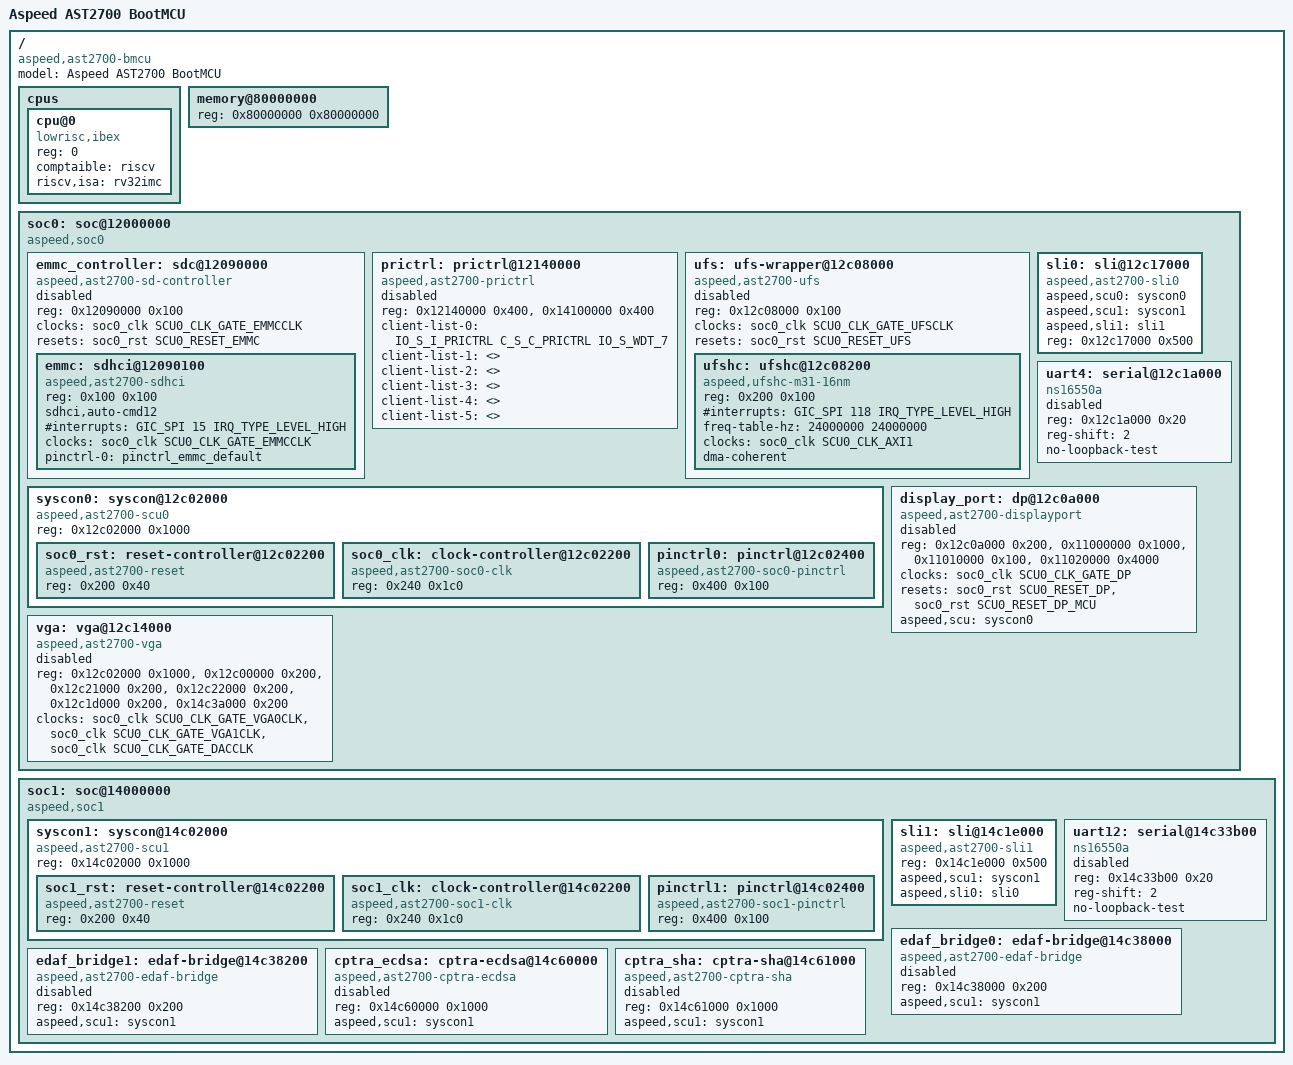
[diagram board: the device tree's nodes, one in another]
// SPDX-License-Identifier: GPL-2.0+
#include <dt-bindings/interrupt-controller/arm-gic.h>
#include <dt-bindings/gpio/aspeed-gpio.h>
#include <dt-bindings/clock/ast2700-clock.h>
#include <dt-bindings/reset/ast2700-reset.h>
#include <dt-bindings/soc/ast2700-prictrl.h>

/ {
	model = "Aspeed AST2700 BootMCU";
	compatible = "aspeed,ast2700-bmcu";
	#address-cells = <1>;
	#size-cells = <1>;

	cpus {
		#address-cells = <1>;
		#size-cells = <0>;

		cpu@0 {
			compatible = "lowrisc,ibex";
			device_type = "cpu";
			reg = <0>;
			comptaible = "riscv";
			riscv,isa = "rv32imc";
		};
	};

	memory@80000000 {
		reg = <0x80000000 0x80000000>;
	};

	soc0: soc@12000000 {
		compatible = "aspeed,soc0","simple-bus";
		#address-cells = <1>;
		#size-cells = <1>;
		ranges;

		emmc_controller: sdc@12090000 {
			compatible = "aspeed,ast2700-sd-controller";
			reg = <0x12090000 0x100>;
			#address-cells = <1>;
			#size-cells = <1>;
			clocks = <&soc0_clk SCU0_CLK_GATE_EMMCCLK>;
			resets = <&soc0_rst SCU0_RESET_EMMC>;
			ranges = <0 0x12090000 0x10000>;
			status = "disabled";

			emmc: sdhci@12090100 {
				compatible = "aspeed,ast2700-sdhci";
				reg = <0x100 0x100>;
				sdhci,auto-cmd12;
				#interrupts = <GIC_SPI 15 IRQ_TYPE_LEVEL_HIGH>;
				clocks = <&soc0_clk SCU0_CLK_GATE_EMMCCLK>;
				pinctrl-names = "default";
				pinctrl-0 = <&pinctrl_emmc_default>;
			};
		};

		prictrl: prictrl@12140000 {
			compatible = "aspeed,ast2700-prictrl";
			reg = <0x12140000 0x400>, <0x14100000 0x400>;
			client-list-0 = <IO_S_I_PRICTRL C_S_C_PRICTRL IO_S_WDT_7>;
			client-list-1 = <>;
			client-list-2 = <>;
			client-list-3 = <>;
			client-list-4 = <>;
			client-list-5 = <>;
			status = "disable";
		};

		ufs: ufs-wrapper@12c08000 {
			compatible = "aspeed,ast2700-ufs";
			reg = <0x12c08000 0x100>;
			#address-cells = <1>;
			#size-cells = <1>;
			ranges = <0 0x12c08000 0x400>;
			clocks = <&soc0_clk SCU0_CLK_GATE_UFSCLK>;
			resets = <&soc0_rst SCU0_RESET_UFS>;
			status = "disabled";

			ufshc: ufshc@12c08200 {
				compatible = "aspeed,ufshc-m31-16nm", "jedec,ufs-2.0";
				reg = <0x200 0x100>;
				#interrupts = <GIC_SPI 118 IRQ_TYPE_LEVEL_HIGH>;
				freq-table-hz = <24000000 24000000>;
				clocks = <&soc0_clk SCU0_CLK_AXI1>;
				clock-names = "core_clk";
				dma-coherent;
			};
		};

		syscon0: syscon@12c02000 {
			compatible = "aspeed,ast2700-scu0", "syscon", "simple-mfd";
			reg = <0x12c02000 0x1000>;
			ranges = <0 0x12c02000 0x1000>;
			#address-cells = <1>;
			#size-cells = <1>;

			soc0_rst: reset-controller@12c02200 {
				compatible = "aspeed,ast2700-reset";
				reg = <0x200 0x40>;
				#reset-cells = <1>;
			};

			soc0_clk: clock-controller@12c02200 {
				compatible = "aspeed,ast2700-soc0-clk";
				reg = <0x240 0x1c0>;
				#clock-cells = <1>;
			};

			pinctrl0: pinctrl@12c02400 {
				compatible = "aspeed,ast2700-soc0-pinctrl";
				reg = <0x400 0x100>;
			};
		};

		sli0: sli@12c17000 {
			compatible = "aspeed,ast2700-sli0";
			aspeed,scu0 = <&syscon0>;
			aspeed,scu1 = <&syscon1>;
			aspeed,sli1 = <&sli1>;
			reg = <0x12c17000 0x500>;
		};

		uart4: serial@12c1a000 {
			compatible = "ns16550a";
			reg = <0x12c1a000 0x20>;
			reg-shift = <2>;
			no-loopback-test;
			status = "disabled";
		};

		display_port: dp@12c0a000 {
			compatible = "aspeed,ast2700-displayport";
			reg = <0x12c0a000 0x200>,
			      <0x11000000 0x1000>,
			      <0x11010000 0x100>,
			      <0x11020000 0x4000>;
			clocks = <&soc0_clk SCU0_CLK_GATE_DP>;
			resets = <&soc0_rst SCU0_RESET_DP>, <&soc0_rst SCU0_RESET_DP_MCU>;
			aspeed,scu = <&syscon0>;
			status = "disabled";
		};

		vga: vga@12c14000 {
			compatible = "aspeed,ast2700-vga";
			reg = <0x12c02000 0x1000>, <0x12c00000 0x200>,
			      <0x12c21000 0x200>, <0x12c22000 0x200>,
			      <0x12c1d000 0x200>, <0x14c3a000 0x200>;
			clocks = <&soc0_clk SCU0_CLK_GATE_VGA0CLK>,
				 <&soc0_clk SCU0_CLK_GATE_VGA1CLK>,
				 <&soc0_clk SCU0_CLK_GATE_DACCLK>;
			status = "disabled";
		};
	};

	soc1: soc@14000000 {
		compatible = "aspeed,soc1","simple-bus";
		#address-cells = <1>;
		#size-cells = <1>;
		ranges;

		syscon1: syscon@14c02000 {
			compatible = "aspeed,ast2700-scu1", "syscon", "simple-mfd";
			reg = <0x14c02000 0x1000>;
			ranges = <0 0x14c02000 0x1000>;
			#address-cells = <1>;
			#size-cells = <1>;

			soc1_rst: reset-controller@14c02200 {
				compatible = "aspeed,ast2700-reset";
				reg = <0x200 0x40>;
				#reset-cells = <1>;
			};

			soc1_clk: clock-controller@14c02200 {
				compatible = "aspeed,ast2700-soc1-clk";
				reg = <0x240 0x1c0>;
				#clock-cells = <1>;
			};

			pinctrl1: pinctrl@14c02400 {
				compatible = "aspeed,ast2700-soc1-pinctrl";
				reg = <0x400 0x100>;
			};
		};

		sli1: sli@14c1e000 {
			compatible = "aspeed,ast2700-sli1";
			reg = <0x14c1e000 0x500>;
			aspeed,scu1 = <&syscon1>;
			aspeed,sli0 = <&sli0>;
		};

		uart12: serial@14c33b00 {
			compatible = "ns16550a";
			reg = <0x14c33b00 0x20>;
			reg-shift = <2>;
			no-loopback-test;
			status = "disabled";
		};

		edaf_bridge0: edaf-bridge@14c38000 {
			compatible = "aspeed,ast2700-edaf-bridge";
			reg = <0x14c38000 0x200>;
			aspeed,scu1 = <&syscon1>;
			status = "disabled";
		};

		edaf_bridge1: edaf-bridge@14c38200 {
			compatible = "aspeed,ast2700-edaf-bridge";
			reg = <0x14c38200 0x200>;
			aspeed,scu1 = <&syscon1>;
			status = "disabled";
		};

		cptra_ecdsa: cptra-ecdsa@14c60000 {
			compatible = "aspeed,ast2700-cptra-ecdsa";
			reg = <0x14c60000 0x1000>;
			aspeed,scu1 = <&syscon1>;
			status = "disabled";
		};

		cptra_sha: cptra-sha@14c61000 {
			compatible = "aspeed,ast2700-cptra-sha";
			reg = <0x14c61000 0x1000>;
			aspeed,scu1 = <&syscon1>;
			status = "disabled";
		};
	};
};
